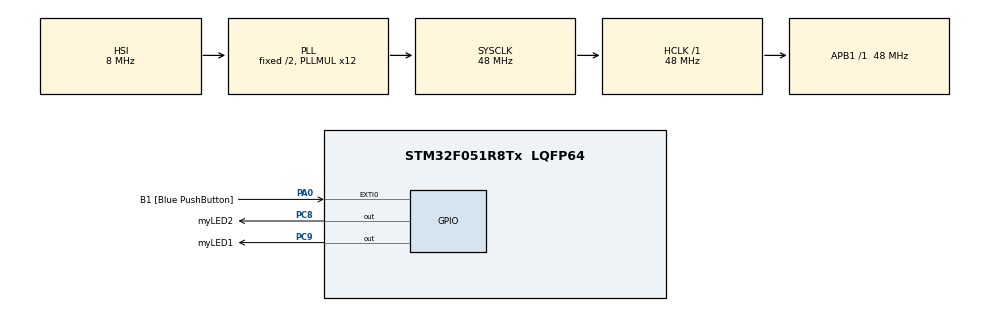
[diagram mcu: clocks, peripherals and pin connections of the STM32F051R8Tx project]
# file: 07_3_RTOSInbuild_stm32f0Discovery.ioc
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FREERTOS.Tasks01=Task01,0,128,StartTask01,Default,NULL,Dynamic,NULL,NULL;Task02,0,128,StartTask02,Default,NULL,Dynamic,NULL,NULL
Mcu.Family=STM32F0
Mcu.Name=STM32F051R8Tx
Mcu.Package=LQFP64
PA0.GPIO_Label=B1 [Blue PushButton]
PA0.GPIO_ModeDefaultEXTI=GPIO_MODE_EVT_RISING
PA0.Signal=GPXTI0
PA13.GPIO_Label=SWDIO
PA13.Signal=SYS_SWDIO
PA14.GPIO_Label=SWCLK
PA14.Signal=SYS_SWCLK
PC8.GPIO_Label=myLED2
PC8.Signal=GPIO_Output
PC9.GPIO_Label=myLED1
PC9.Signal=GPIO_Output
ProjectManager.HeapSize=0x200
ProjectManager.StackSize=0x400
ProjectManager.TargetToolchain=STM32CubeIDE
RCC.AHBFreq_Value=48000000
RCC.APB1Freq_Value=48000000
RCC.APB1TimFreq_Value=48000000
RCC.HCLKFreq_Value=48000000
RCC.PLLMUL=RCC_PLL_MUL12
RCC.SYSCLKFreq_VALUE=48000000
RCC.SYSCLKSource=RCC_SYSCLKSOURCE_PLLCLK
VP_FREERTOS_VS_CMSIS_V1.Mode=CMSIS_V1
board=STM32F0DISCOVERY

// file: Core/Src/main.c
/* USER CODE BEGIN Header */
/**
  ******************************************************************************
  * @file           : main.c
  * @brief          : Main program body
  ******************************************************************************
  * @attention
  *
  * <h2><center>&copy; Copyright (c) 2023 STMicroelectronics.
  * All rights reserved.</center></h2>
  *
  * This software component is licensed by ST under BSD 3-Clause license,
  * the "License"; You may not use this file except in compliance with the
  * License. You may obtain a copy of the License at:
  *                        opensource.org/licenses/BSD-3-Clause
  *
  ******************************************************************************
  */
/* USER CODE END Header */
#include "main.h"
#include "cmsis_os.h"

osThreadId Task01Handle;
osThreadId Task02Handle;

void SystemClock_Config(void);
static void MX_GPIO_Init(void);
void StartTask01(void const * argument);
void StartTask02(void const * argument);

int main(void)
{

  /* MCU Configuration--------------------------------------------------------*/

  /* Reset of all peripherals, Initializes the Flash interface and the Systick. */
  HAL_Init();

  /* Configure the system clock */
  SystemClock_Config();

  /* Initialize all configured peripherals */
  MX_GPIO_Init();

  /* Create the thread(s) */
  /* definition and creation of Task01 */
  osThreadDef(Task01, StartTask01, osPriorityNormal, 0, 128);
  Task01Handle = osThreadCreate(osThread(Task01), NULL);

  /* definition and creation of Task02 */
  osThreadDef(Task02, StartTask02, osPriorityNormal, 0, 128);
  Task02Handle = osThreadCreate(osThread(Task02), NULL);

  /* Start scheduler */
  osKernelStart();

  /* We should never get here as control is now taken by the scheduler */
  /* Infinite loop */
  while (1)
  {

  }
}

void SystemClock_Config(void)
{
  RCC_OscInitTypeDef RCC_OscInitStruct = {0};
  RCC_ClkInitTypeDef RCC_ClkInitStruct = {0};

  /** Initializes the RCC Oscillators according to the specified parameters
  * in the RCC_OscInitTypeDef structure.
  */
  RCC_OscInitStruct.OscillatorType = RCC_OSCILLATORTYPE_HSI;
  RCC_OscInitStruct.HSIState = RCC_HSI_ON;
  RCC_OscInitStruct.HSICalibrationValue = RCC_HSICALIBRATION_DEFAULT;
  RCC_OscInitStruct.PLL.PLLState = RCC_PLL_ON;
  RCC_OscInitStruct.PLL.PLLSource = RCC_PLLSOURCE_HSI;
  RCC_OscInitStruct.PLL.PLLMUL = RCC_PLL_MUL12;
  RCC_OscInitStruct.PLL.PREDIV = RCC_PREDIV_DIV1;
  if (HAL_RCC_OscConfig(&RCC_OscInitStruct) != HAL_OK)
  {
    Error_Handler();
  }
  /** Initializes the CPU, AHB and APB buses clocks
  */
  RCC_ClkInitStruct.ClockType = RCC_CLOCKTYPE_HCLK|RCC_CLOCKTYPE_SYSCLK
                              |RCC_CLOCKTYPE_PCLK1;
  RCC_ClkInitStruct.SYSCLKSource = RCC_SYSCLKSOURCE_PLLCLK;
  RCC_ClkInitStruct.AHBCLKDivider = RCC_SYSCLK_DIV1;
  RCC_ClkInitStruct.APB1CLKDivider = RCC_HCLK_DIV1;

  if (HAL_RCC_ClockConfig(&RCC_ClkInitStruct, FLASH_LATENCY_1) != HAL_OK)
  {
    Error_Handler();
  }
}

static void MX_GPIO_Init(void)
{
  GPIO_InitTypeDef GPIO_InitStruct = {0};

  /* GPIO Ports Clock Enable */
  __HAL_RCC_GPIOA_CLK_ENABLE();
  __HAL_RCC_GPIOC_CLK_ENABLE();

  /*Configure GPIO pin Output Level */
  HAL_GPIO_WritePin(GPIOC, myLED2_Pin|myLED1_Pin, GPIO_PIN_RESET);

  /*Configure GPIO pin : B1_Pin */
  GPIO_InitStruct.Pin = B1_Pin;
  GPIO_InitStruct.Mode = GPIO_MODE_EVT_RISING;
  GPIO_InitStruct.Pull = GPIO_NOPULL;
  HAL_GPIO_Init(B1_GPIO_Port, &GPIO_InitStruct);

  /*Configure GPIO pins : myLED2_Pin myLED1_Pin */
  GPIO_InitStruct.Pin = myLED2_Pin|myLED1_Pin;
  GPIO_InitStruct.Mode = GPIO_MODE_OUTPUT_PP;
  GPIO_InitStruct.Pull = GPIO_NOPULL;
  GPIO_InitStruct.Speed = GPIO_SPEED_FREQ_LOW;
  HAL_GPIO_Init(GPIOC, &GPIO_InitStruct);

}

void StartTask01(void const * argument)
{
  /* USER CODE BEGIN 5 */
  /* Infinite loop */
  for(;;)
  {
	  HAL_GPIO_TogglePin(myLED1_GPIO_Port, myLED1_Pin);
    //osDelay(1);
  }
  /* USER CODE END 5 */
}

void StartTask02(void const * argument)
{
  /* USER CODE BEGIN StartTask02 */
  /* Infinite loop */
  for(;;)
  {
	  HAL_GPIO_TogglePin(myLED2_GPIO_Port, myLED2_Pin);
    //osDelay(1);
  }
  /* USER CODE END StartTask02 */
}

void Error_Handler(void)
{
  __disable_irq();
  while (1)
  {
  }
}

/************************ (C) COPYRIGHT STMicroelectronics *****END OF FILE****/
